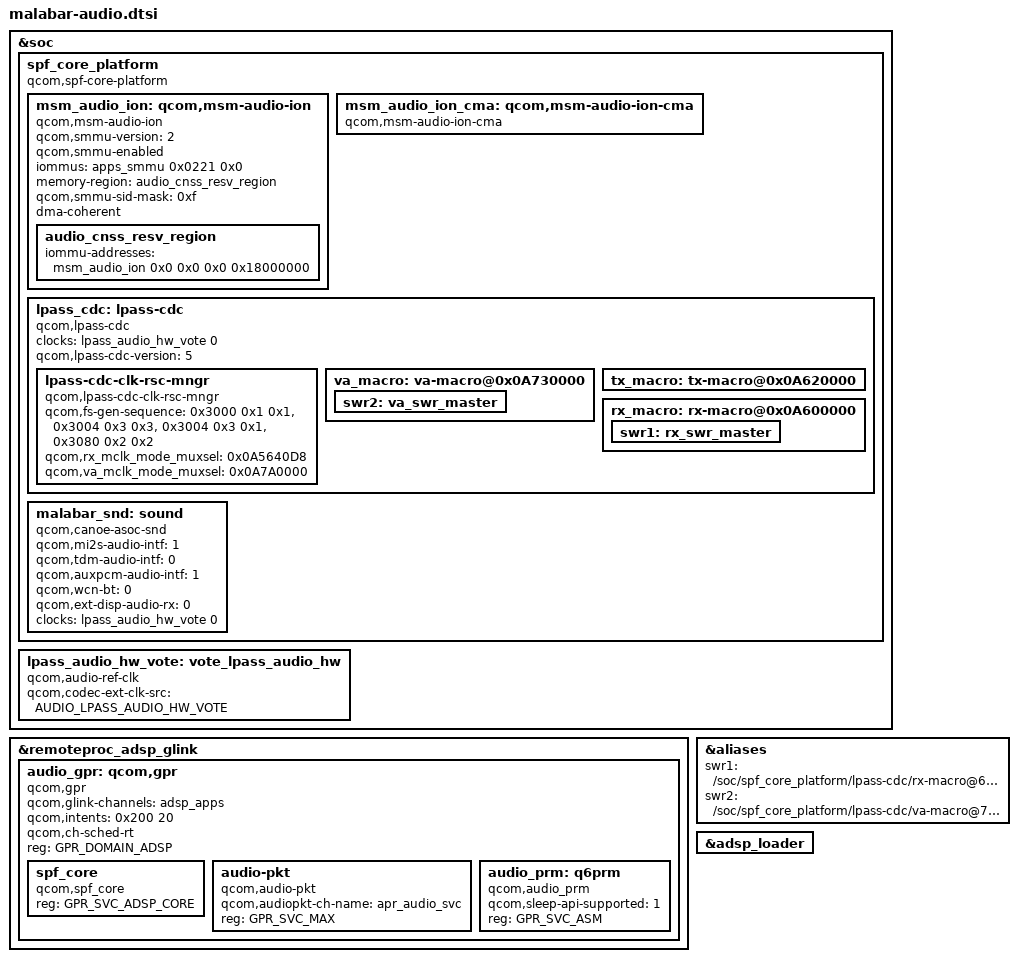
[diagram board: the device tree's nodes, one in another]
//
/* Copyright (c) Qualcomm Technologies, Inc. and/or its subsidiaries.
 * SPDX-License-Identifier: BSD-3-Clause
 */

#include <bindings/qcom,audio-ext-clk.h>
#include <bindings/qcom,gpr.h>
#include "msm-audio-lpass.dtsi"
&soc {
	spf_core_platform: spf_core_platform {
		compatible = "qcom,spf-core-platform";
	};

	lpass_audio_hw_vote: vote_lpass_audio_hw {
		compatible = "qcom,audio-ref-clk";
		qcom,codec-ext-clk-src = <AUDIO_LPASS_AUDIO_HW_VOTE>;
		#clock-cells = <1>;
	};
};

&remoteproc_adsp_glink {
	audio_gpr: qcom,gpr {
		compatible = "qcom,gpr";
		qcom,glink-channels = "adsp_apps";
		qcom,intents = <0x200 20>;
		qcom,ch-sched-rt;
		reg = <GPR_DOMAIN_ADSP>;

		spf_core {
			compatible = "qcom,spf_core";
			reg = <GPR_SVC_ADSP_CORE>;
		};

		audio-pkt {
			compatible = "qcom,audio-pkt";
			qcom,audiopkt-ch-name = "apr_audio_svc";
			reg = <GPR_SVC_MAX>;
		};

		audio_prm: q6prm {
			compatible = "qcom,audio_prm";
			qcom,sleep-api-supported = <1>;
			reg = <GPR_SVC_ASM>;
		};
	};
};

&spf_core_platform {
	#address-cells = <2>;
	#size-cells = <2>;
	msm_audio_ion: qcom,msm-audio-ion {
		compatible = "qcom,msm-audio-ion";
		qcom,smmu-version = <2>;
		qcom,smmu-enabled;
		iommus = <&apps_smmu 0x0221 0x0>;
		memory-region = <&audio_cnss_resv_region>;
		qcom,smmu-sid-mask = /bits/ 64 <0xf>;
		dma-coherent;

		audio_cnss_resv_region: audio_cnss_resv_region {
			iommu-addresses = <&msm_audio_ion 0x0 0x0 0x0 0x18000000>;
		};
	};

	msm_audio_ion_cma: qcom,msm-audio-ion-cma {
		compatible = "qcom,msm-audio-ion-cma";
	};

	lpass_cdc: lpass-cdc {
		compatible = "qcom,lpass-cdc";
		clock-names = "lpass_audio_hw_vote";
		clocks = <&lpass_audio_hw_vote 0>;
		qcom,lpass-cdc-version = <5>;
		lpass-cdc-clk-rsc-mngr {
			compatible = "qcom,lpass-cdc-clk-rsc-mngr";
			qcom,fs-gen-sequence = <0x3000 0x1 0x1>, <0x3004 0x3 0x3>,
					<0x3004 0x3 0x1>, <0x3080 0x2 0x2>;
			qcom,rx_mclk_mode_muxsel = <0x0A5640D8>;
			qcom,va_mclk_mode_muxsel = <0x0A7A0000>;
		};

		va_macro: va-macro@0x0A730000 {
			swr2: va_swr_master {
			};
		};

		tx_macro: tx-macro@0x0A620000 {
		};

		rx_macro: rx-macro@0x0A600000 {
			swr1: rx_swr_master {
			};
		};

	};

	malabar_snd: sound {
		compatible = "qcom,canoe-asoc-snd";
		qcom,mi2s-audio-intf = <1>;
		qcom,tdm-audio-intf = <0>;
		qcom,auxpcm-audio-intf = <1>;
		qcom,wcn-bt = <0>;
		qcom,ext-disp-audio-rx = <0>;
		clock-names = "lpass_audio_hw_vote";
		clocks = <&lpass_audio_hw_vote 0>;
	};
};

&aliases {
	swr1 = "/soc/spf_core_platform/lpass-cdc/rx-macro@6AC0000/rx_swr_master";
	swr2 = "/soc/spf_core_platform/lpass-cdc/va-macro@7660000/va_swr_master";
};

&adsp_loader {
	/delete-property/ qcom,adsp-state;
};
